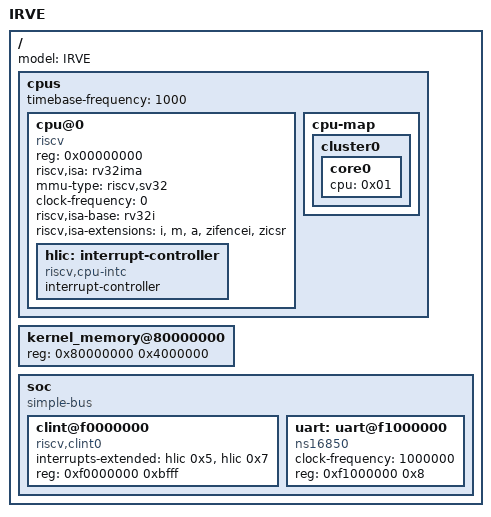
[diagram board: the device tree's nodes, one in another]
/**
 * File:    irve.dts
 * Brief:   The IRVE Device Tree for the Linux kernel
 * 
 * Copyright (C) 2023-2024 John Jekel
 * See the LICENSE file at the root of the project for licensing info.
 * 
 * AFTER COMPILING THIS with `dtc`, IT IS IMPERATIVE IT IS PLACED IN MEMORY AT
 * A LOCATION ALIGNED TO 8 BYTES. THIS TOOK ME FOREVER TO FIGURE OUT. DON'T BE ME.
 *
 * Compile with `dtc ./irve.dts -o ./irve.dtb`
 *
 * Partialy based on https://github.com/cnlohr/mini-rv32ima/blob/master/configs/minimal.dts
 * Also useful: https://github.com/riscv-non-isa/riscv-device-tree-doc/blob/master/bindings/riscv/cpus.txt
 * https://github.com/westerndigitalcorporation/RISC-V-Linux/blob/master/linux/Documentation/devicetree/bindings/interrupt-controller/riscv%2Ccpu-intc.txt
 * https://github.com/PiMaker/rvc/blob/master/dts.dts
 *
 * Useful about timer stuffs:
 * https://patchwork.kernel.org/project/linux-riscv/cover/20211007123632.697666-1-anup.patel@wdc.com/
 *
 * FIXME for S-mode using the SBI instead of the clint, we may need to advertize SBI features via a (seperate) device tree,
 * ex. using the riscv,timer device tree property
 *
*/

/dts-v1/;

/ {
    #address-cells = <1>;
    #size-cells = <1>;
    model = "IRVE";

    cpus {
        #address-cells = <0x01>;
        #size-cells = <0x00>;
        timebase-frequency = <1000>;//mtime ticks at 1kHz

        cpu@0 {
            device_type = "cpu";
            reg = <0x00000000>;//mhartid is 0
            status = "okay";//The CPU begins online
            compatible = "riscv";
            riscv,isa = "rv32ima";
            mmu-type = "riscv,sv32";
            clock-frequency = <0>;//mcycle ticks at an unknown rate (this is an emulator)
            riscv,isa-base = "rv32i";
            riscv,isa-extensions = "i", "m", "a", "zifencei", "zicsr";

            //The "Hart Level Interrupt Controller" (aka the built-in CPU interrupt controller with 3 sources)
            hlic: interrupt-controller {
                #address-cells = <1>;
                #interrupt-cells = <1>;
                interrupt-controller;
                compatible = "riscv,cpu-intc";
            };
        };

         cpu-map {
            cluster0 {
                core0 {
                    cpu = <0x01>;
                };
            };
        };
    };

    //We don't map it the lower memory used by the bootloader so the kernel doesn't interfere with it
    kernel_memory@80000000 {
        device_type = "memory";
        //Starts at 0x80000000 and is 64MB long
        reg = <0x80000000 0x4000000>;
    };

    soc {
        #address-cells = <1>;
        #size-cells = <1>;
        compatible = "simple-bus";
        ranges;

        clint@f0000000 {
            interrupts-extended = <&hlic 0x5 &hlic 0x7>;//Connects to the standard RISC-V timer interrupt lines
            reg = <0xf0000000 0xbfff>;//Quite a big address space for timecmp registers and software interrupt registers
            compatible = "riscv,clint0";
        };

        uart: uart@f1000000 {
            //For some reason letting the kernel know the UART can interrupt it makes it unhappy.
            //It gets stuck on WARN_ON(...interrupt is per cpu devid...) in the kernel for some reason.
            //No matter though, polling the UART is fine (but we still need timer interrupts for that, which thankfully do work)
            //interrupts-extended = <&hlic 0x9 &hlic 0x11>;//Connects to the standard RISC-V external interrupt lines

            clock-frequency = <1000000>;//Emulated UART has no real clock, but 0 doesn't work here; put 1 MHz as a sane value
            reg = <0xf1000000 0x8>;//A 16550A only has 8 registers, each 1 byte
            //Technically IRVE doesn't implement the 16850, however it's close enough and doing this makes things much smoother
            //due to the larger FIFO size (so the kernel sends more at once).
            compatible = "ns16850";
            //compatible = "ns16550a";
        };
    };
};
